# R7KA8D2AD register map
Vendor: Renesas Electronics Corporation; Series: RA8; File version: 1.10.02
CPU: CM85 r0p2, little endian, MPU, FPU, VTOR, 4 interrupt priority bits, 96 interrupts
Registers are 32-bit, read-write, reset 0x0 unless marked. A register's access mark holds for its fields unless they carry their own. Offsets are from the block's base; [hi:lo] are bit positions; {n}, {i} and the like mark numbered series.

## DMAC00 — Direct memory access controller 0
Base 0x4000A000
Same registers: DMAC01 0x4000A040, DMAC02 0x4000A080, DMAC03 0x4000A0C0, DMAC04 0x4000A100, DMAC05 0x4000A140, DMAC06 0x4000A180, DMAC07 0x4000A1C0, DMAC{n:02}_NS {0x5000A000+0x40*n} (n=0..7)
0x00 DMSAR — DMA Source Address Register
0x04 DMDAR — DMA Destination Address Register
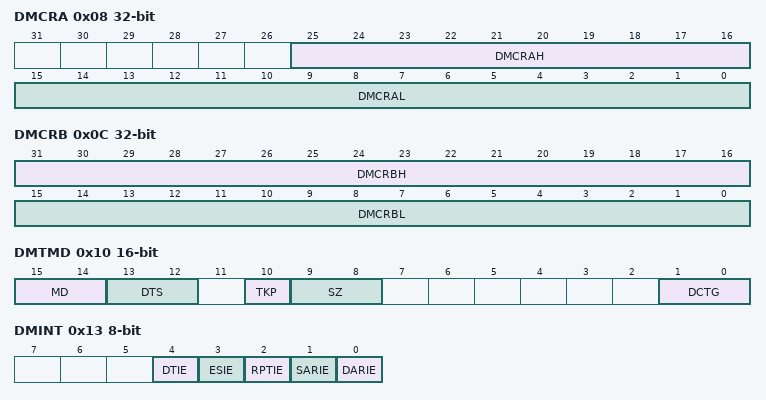
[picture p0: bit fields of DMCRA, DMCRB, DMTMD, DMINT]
0x08 DMCRA — DMA Transfer Count Register
  [25:16] DMCRAH — Upper bits of transfer count
  [15:0] DMCRAL — Lower bits of transfer count
0x0C DMCRB — DMA Block Transfer Count Register
  [31:16] DMCRBH — Specifies the number of block, repeat or repeat-block transfer operations.
  [15:0] DMCRBL — Functions as a number of block, repeat or repeat-block transfer counter.
0x10 DMTMD 16-bit — DMA Transfer Mode Register
  [15:14] MD — Transfer Mode Select
    0=Normal transfer; 1=Repeat transfer; 2=Block transfer; 3=Repeat-block transfer
  [13:12] DTS — Repeat Area Select
    0=The destination is specified as the repeat area or block area; 1=The source is specified as the repeat area or block area; 2=The repeat area or block area is not specified; 3=Setting prohibited
  [10] TKP — Transfer Keeping
    0=Transfer is stopped by completion of specified total number of transfer operations; 1=Transfer is not stopped by completion of specified total number of transfer operations (free-running)
  [9:8] SZ — Transfer Data Size Select
    0=8 bits; 1=16 bits; 2=32 bits; 3=64 bits
  [1:0] DCTG — Transfer Request Source Select
    0=Software request; 1=Hardware request; 2=Setting prohibited; 3=Setting prohibited
0x13 DMINT 8-bit — DMA Interrupt Setting Register
  [4] DTIE — Transfer End Interrupt Enable
    0=Disables the transfer end interrupt request; 1=Enables the transfer end interrupt request
  [3] ESIE — Transfer Escape End Interrupt Enable
    0=Disables the transfer escape end interrupt request; 1=Enables the transfer escape end interrupt request
  [2] RPTIE — Repeat Size End Interrupt Enable
    0=Disables the repeat size end interrupt request; 1=Enables the repeat size end interrupt request
  [1] SARIE — Source Address Extended Repeat Area Overflow Interrupt Enable
    0=Disables an interrupt request for an extended repeat area overflow on the source address; 1=Enables an interrupt request for an extended repeat area overflow on the source address
  [0] DARIE — Destination Address Extended Repeat Area Overflow Interrupt Enable
    0=Disables an interrupt request for an extended repeat area overflow on the destination address; 1=Enables an interrupt request for an extended repeat area overflow on the destination address
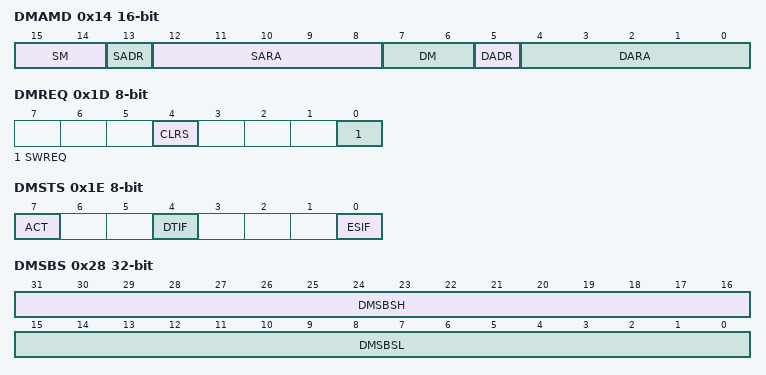
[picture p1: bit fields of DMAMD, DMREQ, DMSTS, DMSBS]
0x14 DMAMD 16-bit — DMA Address Mode Register
  [15:14] SM — Source Address Update Mode
    0=Source address is fixed; 1=Offset addition; 2=Source address is incremented; 3=Source address is decremented
  [13] SADR — Source Address Update Select After Reload
    0=Only reloading; 1=Add index after reloading
  [12:8] SARA — Source Address Extended Repeat Area
  [7:6] DM — Destination Address Update Mode
    0=Destination address is fixed; 1=Offset addition; 2=Destination address is incremented; 3=Destination address is decremented
  [5] DADR — Destination Address Update Select After Reload
    0=Only reloading; 1=Add index after reloading
  [4:0] DARA — Destination Address Extended Repeat Area
0x18 DMOFR — DMA Offset Register
0x1C DMCNT 8-bit — DMA Transfer Enable Register
  [0] DTE — DMA Transfer Enable
    0=Disables DMA transfer; 1=Enables DMA transfer
0x1D DMREQ 8-bit — DMA Software Start Register
  [4] CLRS — DMA Software Start Bit Auto Clear Select
    0=SWREQ bit is cleared after DMA transfer is started by software; 1=SWREQ bit is not cleared after DMA transfer is started by software
  [0] SWREQ — DMA Software Start
    0=DMA transfer is not requested; 1=DMA transfer is requested
0x1E DMSTS 8-bit — DMA Status Register
  [7] ACT ro — DMAC Active Flag
    0=DMAC is in the idle state; 1=DMAC is operating
  [4] DTIF — Transfer End Interrupt Flag
    0=A transfer end interrupt has not been generated; 1=A transfer end interrupt has been generated
  [0] ESIF — Transfer Escape End Interrupt Flag
    0=A transfer escape end interrupt has not been generated; 1=A transfer escape end interrupt has been generated
0x20 DMSRR — DMA Source Reload Address Register
0x24 DMDRR — DMA Destination Reload Address Register
0x28 DMSBS — DMA Source Buffer Size Register
  [31:16] DMSBSH — Specifies the repeat-area size in repeat-block transfer mode
  [15:0] DMSBSL — Functions as data transfer counter in repeat-block transfer mode
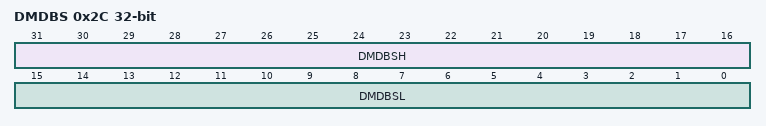
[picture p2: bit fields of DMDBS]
0x2C DMDBS — DMA Destination Buffer Size Register
  [31:16] DMDBSH — Specifies the repeat-area size in repeat-block transfer mode.
  [15:0] DMDBSL — Functions as data transfer counter in repeat-block transfer mode.
0x30 DMBWR 8-bit — DMA Bufferable Write Enable Register
  [0] BWE — Bufferable Write Enable
    0=Disables Bufferable Write; 1=Enables Bufferable Write
